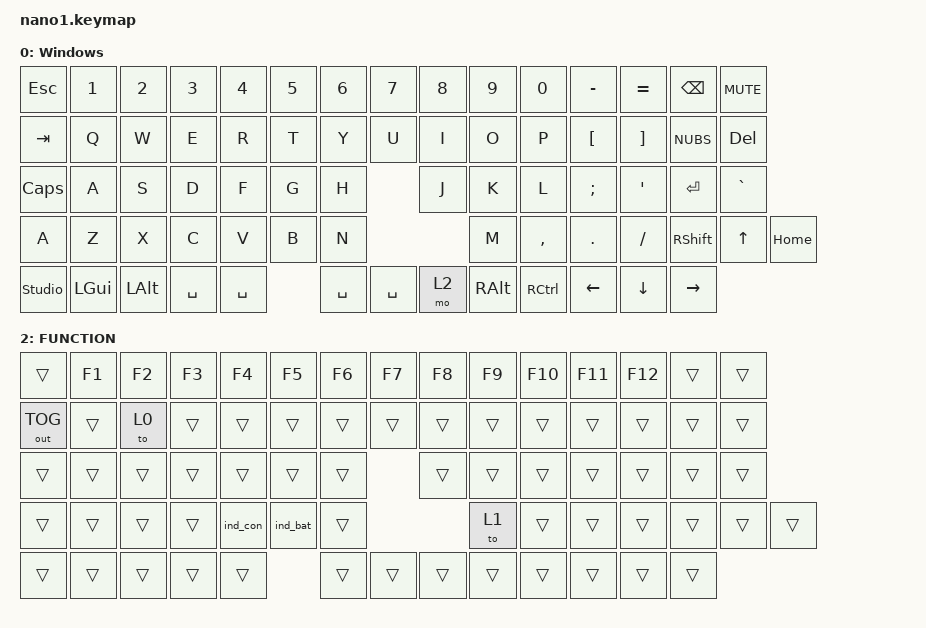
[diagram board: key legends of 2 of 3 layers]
// This file was generated from a template. Edit it to match your keyboard.
// See https://zmk.dev/docs/development/hardware-integration/new-shield for more instructions.

#include <behaviors.dtsi>
#include <dt-bindings/zmk/keys.h>
#include <dt-bindings/zmk/outputs.h>
#include <behaviors/rgbled_widget.dtsi>
#include <dt-bindings/zmk/bt.h>
/ {
    // Define a default keymap here.
    // See https://zmk.dev/docs/development/hardware-integration/new-shield#default-keymap.
    keymap {
        compatible = "zmk,keymap";

        default_layer {
            display-name = "Windows";
            bindings = <
                &kp ESC &kp N1 &kp N2 &kp N3 &kp N4 &kp N5 &kp N6       &kp N7 &kp N8 &kp N9 &kp N0 &kp MINUS &kp EQUAL &kp BSPC &kp C_MUTE // 15 
                &kp TAB       &kp Q &kp W &kp E &kp R &kp T             &kp Y  &kp U &kp I &kp O &kp P &kp LBKT &kp RBKT &kp NUBS &kp DEL // 15
                &kp CAPS      &kp A &kp S &kp D &kp F &kp G             &kp H  &kp J &kp K &kp L &kp SEMI &kp SQT &kp ENTER  &kp GRAVE // 14
                &kp A    &kp Z &kp X &kp C &kp V &kp B             &kp N  &kp M &kp COMMA &kp DOT &kp FSLH &kp RSHIFT &kp UP &kp HOME // 14
                &studio_unlock  &kp LGUI &kp LALT  &kp SPACE &kp SPACE       &kp SPACE &kp SPACE &mo 2 &kp RALT &kp RCTRL &kp LEFT &kp DOWN &kp RIGHT   // 13
                >;
        };
        MAC {
            display-name = "MAC";
            bindings = <
                &trans &trans &trans &trans &trans &trans &trans        &trans &trans &trans &trans &trans &trans &trans &trans 
                &trans &trans &trans &trans &trans &trans               &trans &trans &trans &trans &trans &trans &trans &trans &trans 
                &trans &trans &trans &trans &trans &trans               &trans &trans &trans &trans &trans &trans &trans &trans 
                &trans &trans &trans &trans &trans &trans               &trans &trans &trans &trans &trans &trans &trans &trans 
                // &kp LGUI &kp LALT &kp LCTRL &trans &trans               &trans &trans &trans &trans &kp RGUI &trans &trans &trans 
            >;
        };
        FUNCTION {
            display-name = "FUNCTION";
            bindings = <
                &trans &kp F1 &kp F2 &kp F3 &kp F4 &kp F5 &kp F6        &kp F7 &kp F8 &kp F9 &kp F10 &kp F11 &kp F12 &trans &trans 
                &out OUT_TOG &trans &to 0 &trans &trans &trans          &trans &trans &trans &trans &trans &trans &trans &trans &trans 
                &trans &trans &trans &trans &trans &trans               &trans &trans &trans &trans &trans &trans &trans &trans 
                &trans &trans &trans &trans &ind_con &ind_bat               &trans &to 1 &trans &trans &trans &trans &trans &trans 
                &trans &trans &trans &trans &trans               &trans &trans &trans &trans &trans &trans &trans &trans 
            >;
        };
    };
};
